AUTOSAR XML (schema 00044)
package /ComponentTypes
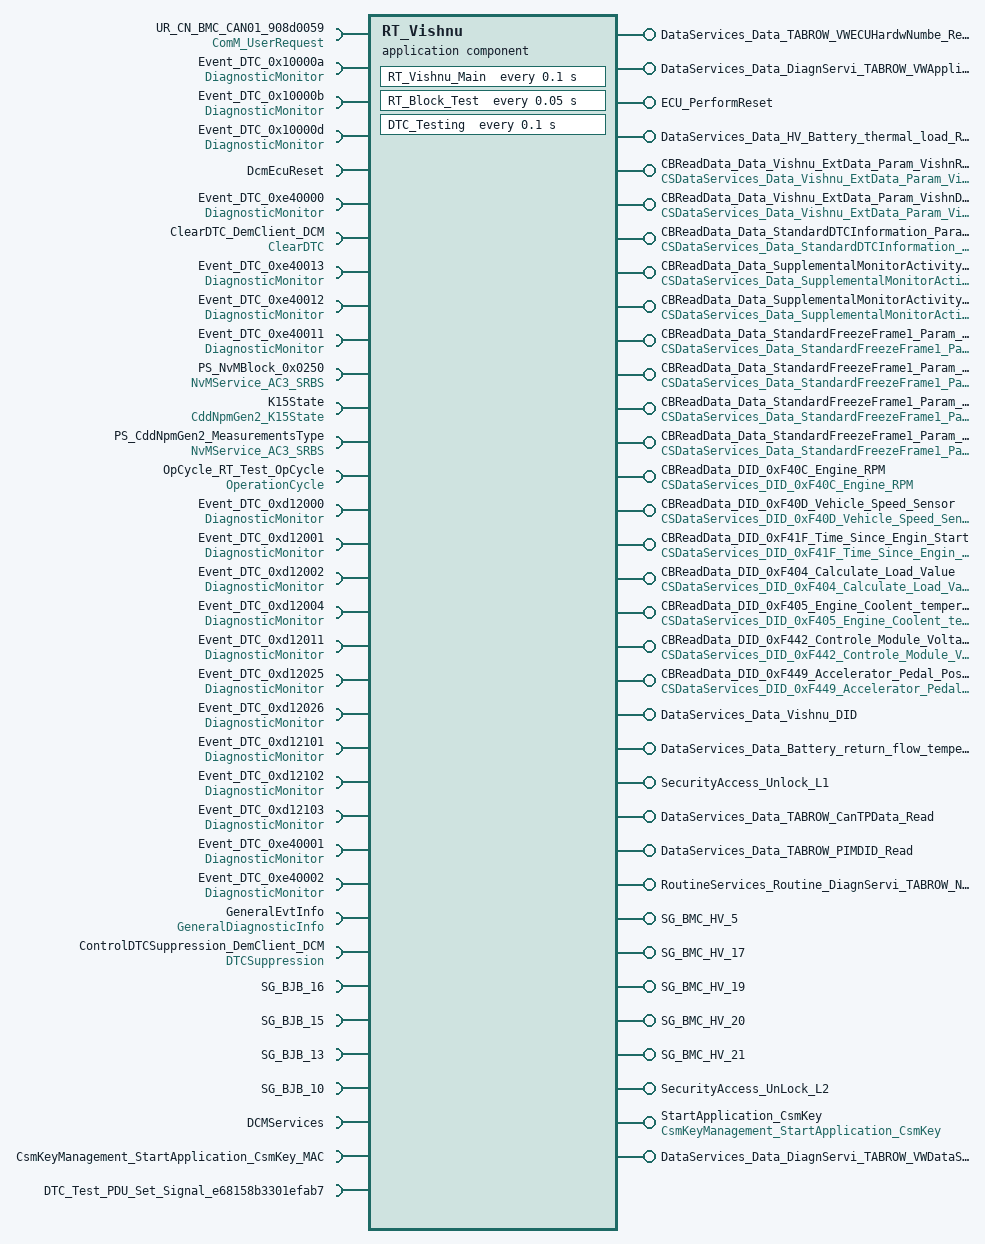
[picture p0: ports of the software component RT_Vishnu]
  application sw component type RT_Vishnu
    require port UR_CN_BMC_CAN01_908d0059: required-com-specs=[RequestComMode, GetCurrentComMode, GetMaxComMode, GetRequestedComMode, GetCurrentPNCComMode], required-interface=ComM_UserRequest
    provide port DataServices_Data_TABROW_VWECUHardwNumbe_Read: provided-com-specs=[{operation=ReadData, queue-length=1}, {operation=ConditionCheckRead, queue-length=1}], provided-interface=DataServices_Data_TABROW_VWECUHardwNumbe_Read
    provide port DataServices_Data_DiagnServi_TABROW_VWAppliSoftwVersiNumbe_Read: provided-com-specs=[{operation=ReadData, queue-length=1}, {operation=ConditionCheckRead, queue-length=1}], provided-interface=DataServices_Data_DiagnServi_TABROW_VWAppliSoftwVersiNumbe_Read
    require port Event_DTC_0x10000a: required-interface=DiagnosticMonitor
      required-com-specs:
        SetEventStatus
        ResetEventStatus
        ResetEventDebounceStatus
        GetEventUdsStatus
        GetEventStatus
        GetEventFailed
        GetEventTested
        GetDTCOfEvent
        GetFaultDetectionCounter
        GetEventFreezeFrameDataEx
        GetEventExtendedDataRecordEx
    require port Event_DTC_0x10000b: required-interface=DiagnosticMonitor
      required-com-specs:
        SetEventStatus
        ResetEventStatus
        ResetEventDebounceStatus
        GetEventUdsStatus
        GetEventStatus
        GetEventFailed
        GetEventTested
        GetDTCOfEvent
        GetFaultDetectionCounter
        GetEventFreezeFrameDataEx
        GetEventExtendedDataRecordEx
    require port Event_DTC_0x10000d: required-interface=DiagnosticMonitor
      required-com-specs:
        SetEventStatus
        ResetEventStatus
        ResetEventDebounceStatus
        GetEventUdsStatus
        GetEventStatus
        GetEventFailed
        GetEventTested
        GetDTCOfEvent
        GetFaultDetectionCounter
        GetEventFreezeFrameDataEx
        GetEventExtendedDataRecordEx
    provide port ECU_PerformReset: mode-switch-sender-com-spec{mode-group=IF_ECU_Perform_Reset_Indication, queue-length=1}, provided-interface=ECU_PerformReset
    require port DcmEcuReset: mode-switch-receiver-com-spec=DcmEcuReset, required-interface=DcmEcuReset
    provide port DataServices_Data_HV_Battery_thermal_load_Read_Data_By_Identifier: provided-com-specs=[{operation=ReadData, queue-length=1}, {operation=ConditionCheckRead, queue-length=1}], provided-interface=DataServices_Data_HV_Battery_thermal_load_Read_Data_By_Identifier
    require port Event_DTC_0xe40000: required-interface=DiagnosticMonitor
      required-com-specs:
        SetEventStatus
        ResetEventStatus
        ResetEventDebounceStatus
        GetEventUdsStatus
        GetEventStatus
        GetEventFailed
        GetEventTested
        GetDTCOfEvent
        GetFaultDetectionCounter
        GetEventFreezeFrameDataEx
        GetEventExtendedDataRecordEx
    provide port CBReadData_Data_Vishnu_ExtData_Param_VishnRes: server-com-spec{operation=ReadData, queue-length=1}, provided-interface=CSDataServices_Data_Vishnu_ExtData_Param_VishnRes
    provide port CBReadData_Data_Vishnu_ExtData_Param_VishnDOB: server-com-spec{operation=ReadData, queue-length=1}, provided-interface=CSDataServices_Data_Vishnu_ExtData_Param_VishnDOB
    provide port CBReadData_Data_StandardDTCInformation_Param_DTCPrior: server-com-spec{operation=ReadData, queue-length=1}, provided-interface=CSDataServices_Data_StandardDTCInformation_Param_DTCPrior
    require port ClearDTC_DemClient_DCM: required-com-specs=[SelectDTC, ClearDTC], required-interface=ClearDTC
    6 x provide port, all with server-com-spec{operation=ReadData, queue-length=1}:
      CBReadData_Data_SupplementalMonitorActivityData_Param_StoreMonitActivRatio: provided-interface=CSDataServices_Data_SupplementalMonitorActivityData_Param_StoreMonitActivRatio
      CBReadData_Data_SupplementalMonitorActivityData_Param_MonitActivNumerCount: provided-interface=CSDataServices_Data_SupplementalMonitorActivityData_Param_MonitActivNumerCount
      CBReadData_Data_StandardFreezeFrame1_Param_TimeStamp_STRUC_Bitfi: provided-interface=CSDataServices_Data_StandardFreezeFrame1_Param_TimeStamp_STRUC_Bitfi
      CBReadData_Data_StandardFreezeFrame1_Param_Reser: provided-interface=CSDataServices_Data_StandardFreezeFrame1_Param_Reser
      CBReadData_Data_StandardFreezeFrame1_Param_KmMilea_1: provided-interface=CSDataServices_Data_StandardFreezeFrame1_Param_KmMilea_1
      CBReadData_Data_StandardFreezeFrame1_Param_AgingCount: provided-interface=CSDataServices_Data_StandardFreezeFrame1_Param_AgingCount
    require port Event_DTC_0xe40013: required-interface=DiagnosticMonitor
      required-com-specs:
        SetEventStatus
        ResetEventStatus
        ResetEventDebounceStatus
        GetEventUdsStatus
        GetEventStatus
        GetEventFailed
        GetEventTested
        GetDTCOfEvent
        GetFaultDetectionCounter
        GetEventFreezeFrameDataEx
        GetEventExtendedDataRecordEx
    require port Event_DTC_0xe40012: required-interface=DiagnosticMonitor
      required-com-specs:
        SetEventStatus
        ResetEventStatus
        ResetEventDebounceStatus
        GetEventUdsStatus
        GetEventStatus
        GetEventFailed
        GetEventTested
        GetDTCOfEvent
        GetFaultDetectionCounter
        GetEventFreezeFrameDataEx
        GetEventExtendedDataRecordEx
    require port Event_DTC_0xe40011: required-interface=DiagnosticMonitor
      required-com-specs:
        SetEventStatus
        ResetEventStatus
        ResetEventDebounceStatus
        GetEventUdsStatus
        GetEventStatus
        GetEventFailed
        GetEventTested
        GetDTCOfEvent
        GetFaultDetectionCounter
        GetEventFreezeFrameDataEx
        GetEventExtendedDataRecordEx
    8 x provide port:
      CBReadData_DID_0xF40C_Engine_RPM: server-com-spec{operation=ReadData, queue-length=1}, provided-interface=CSDataServices_DID_0xF40C_Engine_RPM
      CBReadData_DID_0xF40D_Vehicle_Speed_Sensor: server-com-spec{operation=ReadData, queue-length=1}, provided-interface=CSDataServices_DID_0xF40D_Vehicle_Speed_Sensor
      CBReadData_DID_0xF41F_Time_Since_Engin_Start: server-com-spec{operation=ReadData, queue-length=1}, provided-interface=CSDataServices_DID_0xF41F_Time_Since_Engin_Start
      CBReadData_DID_0xF404_Calculate_Load_Value: server-com-spec{operation=ReadData, queue-length=1}, provided-interface=CSDataServices_DID_0xF404_Calculate_Load_Value
      CBReadData_DID_0xF405_Engine_Coolent_temperature: server-com-spec{operation=ReadData, queue-length=1}, provided-interface=CSDataServices_DID_0xF405_Engine_Coolent_temperature
      CBReadData_DID_0xF442_Controle_Module_Voltage: server-com-spec{operation=ReadData, queue-length=1}, provided-interface=CSDataServices_DID_0xF442_Controle_Module_Voltage
      CBReadData_DID_0xF449_Accelerator_Pedal_Position_D: server-com-spec{operation=ReadData, queue-length=1}, provided-interface=CSDataServices_DID_0xF449_Accelerator_Pedal_Position_D
      DataServices_Data_Vishnu_DID: provided-interface=DataServices_Data_Vishnu_DID
        provided-com-specs:
          operation=ReadData, queue-length=1
          operation=ConditionCheckRead, queue-length=1
          operation=WriteData, queue-length=1
    require port PS_NvMBlock_0x0250: required-com-specs=[GetErrorStatus, SetRamBlockStatus, ReadBlock, WriteBlock, InvalidateNvBlock, EraseBlock], required-interface=NvMService_AC3_SRBS
    provide port DataServices_Data_Battery_return_flow_temperature_Read_Data_By_Identifier: provided-interface=DataServices_Data_Battery_return_flow_temperature_Read_Data_By_Identifier
      provided-com-specs:
        operation=ReadData, queue-length=1
        operation=ConditionCheckRead, queue-length=1
        operation=WriteData, queue-length=1
    provide port SecurityAccess_Unlock_L1: provided-com-specs=[{operation=GetSeed, queue-length=1}, {operation=CompareKey, queue-length=1}], provided-interface=SecurityAccess_Unlock_L1
    require port K15State: client-com-spec=SetK15State, required-interface=CddNpmGen2_K15State
    require port PS_CddNpmGen2_MeasurementsType: required-com-specs=[GetErrorStatus, SetRamBlockStatus, ReadBlock, WriteBlock, InvalidateNvBlock, EraseBlock], required-interface=NvMService_AC3_SRBS
    require port OpCycle_RT_Test_OpCycle: required-com-specs=[GetOperationCycleState, SetOperationCycleState], required-interface=OperationCycle
    provide port DataServices_Data_TABROW_CanTPData_Read: provided-interface=DataServices_Data_TABROW_CanTPData_Read
      provided-com-specs:
        operation=ReadData, queue-length=1
        operation=ConditionCheckRead, queue-length=1
        operation=WriteData, queue-length=1
    provide port DataServices_Data_TABROW_PIMDID_Read: provided-interface=DataServices_Data_TABROW_PIMDID_Read
      provided-com-specs:
        operation=ReadData, queue-length=1
        operation=ConditionCheckRead, queue-length=1
        operation=WriteData, queue-length=1
    provide port RoutineServices_Routine_DiagnServi_TABROW_NewRoutiBasicSetti_Start_Routine: provided-interface=RoutineServices_Routine_DiagnServi_TABROW_NewRoutiBasicSetti_Start_Routine
      provided-com-specs:
        operation=Start, queue-length=1
        operation=Stop, queue-length=1
        operation=RequestResults, queue-length=1
    14 x require port:
      Event_DTC_0xd12000: required-interface=DiagnosticMonitor
        required-com-specs:
          SetEventStatus
          ResetEventStatus
          ResetEventDebounceStatus
          GetEventUdsStatus
          GetEventStatus
          GetEventFailed
          GetEventTested
          GetDTCOfEvent
          GetFaultDetectionCounter
          GetEventFreezeFrameDataEx
          GetEventExtendedDataRecordEx
      Event_DTC_0xd12001: required-interface=DiagnosticMonitor
        required-com-specs:
          SetEventStatus
          ResetEventStatus
          ResetEventDebounceStatus
          GetEventUdsStatus
          GetEventStatus
          GetEventFailed
          GetEventTested
          GetDTCOfEvent
          GetFaultDetectionCounter
          GetEventFreezeFrameDataEx
          GetEventExtendedDataRecordEx
      Event_DTC_0xd12002: required-interface=DiagnosticMonitor
        required-com-specs:
          SetEventStatus
          ResetEventStatus
          ResetEventDebounceStatus
          GetEventUdsStatus
          GetEventStatus
          GetEventFailed
          GetEventTested
          GetDTCOfEvent
          GetFaultDetectionCounter
          GetEventFreezeFrameDataEx
          GetEventExtendedDataRecordEx
      Event_DTC_0xd12004: required-interface=DiagnosticMonitor
        required-com-specs:
          SetEventStatus
          ResetEventStatus
          ResetEventDebounceStatus
          GetEventUdsStatus
          GetEventStatus
          GetEventFailed
          GetEventTested
          GetDTCOfEvent
          GetFaultDetectionCounter
          GetEventFreezeFrameDataEx
          GetEventExtendedDataRecordEx
      Event_DTC_0xd12011: required-interface=DiagnosticMonitor
        required-com-specs:
          SetEventStatus
          ResetEventStatus
          ResetEventDebounceStatus
          GetEventUdsStatus
          GetEventStatus
          GetEventFailed
          GetEventTested
          GetDTCOfEvent
          GetFaultDetectionCounter
          GetEventFreezeFrameDataEx
          GetEventExtendedDataRecordEx
      Event_DTC_0xd12025: required-interface=DiagnosticMonitor
        required-com-specs:
          SetEventStatus
          ResetEventStatus
          ResetEventDebounceStatus
          GetEventUdsStatus
          GetEventStatus
          GetEventFailed
          GetEventTested
          GetDTCOfEvent
          GetFaultDetectionCounter
          GetEventFreezeFrameDataEx
          GetEventExtendedDataRecordEx
      Event_DTC_0xd12026: required-interface=DiagnosticMonitor
        required-com-specs:
          SetEventStatus
          ResetEventStatus
          ResetEventDebounceStatus
          GetEventUdsStatus
          GetEventStatus
          GetEventFailed
          GetEventTested
          GetDTCOfEvent
          GetFaultDetectionCounter
          GetEventFreezeFrameDataEx
          GetEventExtendedDataRecordEx
      Event_DTC_0xd12101: required-interface=DiagnosticMonitor
        required-com-specs:
          SetEventStatus
          ResetEventStatus
          ResetEventDebounceStatus
          GetEventUdsStatus
          GetEventStatus
          GetEventFailed
          GetEventTested
          GetDTCOfEvent
          GetFaultDetectionCounter
          GetEventFreezeFrameDataEx
          GetEventExtendedDataRecordEx
      Event_DTC_0xd12102: required-interface=DiagnosticMonitor
        required-com-specs:
          SetEventStatus
          ResetEventStatus
          ResetEventDebounceStatus
          GetEventUdsStatus
          GetEventStatus
          GetEventFailed
          GetEventTested
          GetDTCOfEvent
          GetFaultDetectionCounter
          GetEventFreezeFrameDataEx
          GetEventExtendedDataRecordEx
      Event_DTC_0xd12103: required-interface=DiagnosticMonitor
        required-com-specs:
          SetEventStatus
          ResetEventStatus
          ResetEventDebounceStatus
          GetEventUdsStatus
          GetEventStatus
          GetEventFailed
          GetEventTested
          GetDTCOfEvent
          GetFaultDetectionCounter
          GetEventFreezeFrameDataEx
          GetEventExtendedDataRecordEx
      Event_DTC_0xe40001: required-interface=DiagnosticMonitor
        required-com-specs:
          SetEventStatus
          ResetEventStatus
          ResetEventDebounceStatus
          GetEventUdsStatus
          GetEventStatus
          GetEventFailed
          GetEventTested
          GetDTCOfEvent
          GetFaultDetectionCounter
          GetEventFreezeFrameDataEx
          GetEventExtendedDataRecordEx
      Event_DTC_0xe40002: required-interface=DiagnosticMonitor
        required-com-specs:
          SetEventStatus
          ResetEventStatus
          ResetEventDebounceStatus
          GetEventUdsStatus
          GetEventStatus
          GetEventFailed
          GetEventTested
          GetDTCOfEvent
          GetFaultDetectionCounter
          GetEventFreezeFrameDataEx
          GetEventExtendedDataRecordEx
      GeneralEvtInfo: required-interface=GeneralDiagnosticInfo
        required-com-specs:
          GetEventUdsStatus
          GetEventStatus
          GetEventFailed
          GetEventTested
          GetDTCOfEvent
          GetFaultDetectionCounter
          GetEventFreezeFrameDataEx
          GetEventExtendedDataRecordEx
          GetEventEnableCondition
          GetDebouncingOfEvent
          GetMonitorStatus
      ControlDTCSuppression_DemClient_DCM: required-com-specs=[SetDTCSuppression, GetDTCSuppression], required-interface=DTCSuppression
    5 x provide port:
      SG_BMC_HV_5: nonqueued-sender-com-spec{data-element=SG_BMC_HV_04, init-value=fields=[BMC_Dev_Freigabe:0, BMC_Flash_Freigabe:0, BMC_HV_04_BZ:0, BMC_HV_04_CRC:0, BMC_Iso_Mode_Anf:0, BMC_UI1_Spannung1_Schalt_Anf:0, BMC_UI1_Spannung2_Schalt_Anf:0, BMC_UI2_Spannung1_Schalt_Anf:0, BMC_UI2_Spannung2_Schalt_Anf:0, SignalVoid_BMC_HV_04_0:0, SignalVoid_BMC_HV_04_1:0, SignalVoid_BMC_HV_04_2:0, SignalVoid_BMC_HV_04_3:0, SignalVoid_BMC_HV_04_4:0, SignalVoid_BMC_HV_04_5:0]}, provided-interface=SG_BMC_HV_5
      SG_BMC_HV_17: nonqueued-sender-com-spec{data-element=SG_BMC_HV_10, init-value=fields=[BMC_Datenuebernahme_Anf:0, BMC_HV_10_BZ:0, BMC_HV_10_CRC:0, BMC_Lebensdauer_Trennelemente:0, BMC_Sperrung_Unterspannung:0, BMC_Status_HV_Spannungssensorik:0, BMC_Status_Trennelemente:0, SignalVoid_BMC_HV_10_0:0, SignalVoid_BMC_HV_10_1:0, SignalVoid_BMC_HV_10_2:0, SignalVoid_BMC_HV_10_3:0]}, provided-interface=SG_BMC_HV_17
      SG_BMC_HV_19: nonqueued-sender-com-spec{data-element=SG_BMC_HV_11, init-value=fields=[BMC_HV_11_BZ:0, BMC_HV_11_CRC:0, BMC_Sperrung_Ueberspannung:0, BMC_Ueberspannungszaehler_CMC01:0, BMC_Ueberspannungszaehler_CMC02:0, BMC_Uebertemperaturzaehler_CMC01:0, BMC_Uebertemperaturzaehler_CMC02:0]}, provided-interface=SG_BMC_HV_19
      SG_BMC_HV_20: nonqueued-sender-com-spec{data-element=SG_BMC_HV_12, init-value=fields=[BMC_HV_12_BZ:0, BMC_HV_12_CRC:0, BMC_Sperrung_Uebertemperatur:0, BMC_Ueberspannungszaehler_CMC03:0, BMC_Ueberspannungszaehler_CMC04:0, BMC_Uebertemperaturzaehler_CMC03:0, BMC_Uebertemperaturzaehler_CMC04:0]}, provided-interface=SG_BMC_HV_20
      SG_BMC_HV_21: nonqueued-sender-com-spec{data-element=SG_BMC_HV_13, init-value=fields=[BMC_HV_13_BZ:0, BMC_HV_13_CRC:0, BMC_Unterspannungszaehler_CMC01:0, BMC_Unterspannungszaehler_CMC02:0, BMC_Unterspannungszaehler_CMC03:0, BMC_Unterspannungszaehler_CMC04:0, SignalVoid_BMC_HV_13_0:0, SignalVoid_BMC_HV_13_1:0]}, provided-interface=SG_BMC_HV_21
    4 x require port:
      SG_BJB_16: nonqueued-receiver-com-spec{data-element=SG_BJB_13, filter=data-filter-type=ALWAYS, init-value=fields=[BJB_13_BZ:0, BJB_13_CRC:0, BJB_Unterspannungszaehler_CMC01:0, BJB_Unterspannungszaehler_CMC02:0, BJB_Unterspannungszaehler_CMC03:0, BJB_Unterspannungszaehler_CMC04:0, SignalVoid_BJB_13_0:0, SignalVoid_BJB_13_1:0]}, required-interface=SG_BJB_16
      SG_BJB_15: nonqueued-receiver-com-spec{data-element=SG_BJB_12, filter=data-filter-type=ALWAYS, init-value=fields=[BJB_12_BZ:0, BJB_12_CRC:0, BJB_Sperrung_Uebertemperatur:0, BJB_Ueberspannungszaehler_CMC03:0, BJB_Ueberspannungszaehler_CMC04:0, BJB_Uebertemperaturzaehler_CMC03:0, BJB_Uebertemperaturzaehler_CMC04:0]}, required-interface=SG_BJB_15
      SG_BJB_13: nonqueued-receiver-com-spec{data-element=SG_BJB_11, filter=data-filter-type=ALWAYS, init-value=fields=[BJB_11_BZ:0, BJB_11_CRC:0, BJB_Sperrung_Ueberspannung:0, BJB_Ueberspannungszaehler_CMC01:0, BJB_Ueberspannungszaehler_CMC02:0, BJB_Uebertemperaturzaehler_CMC01:0, BJB_Uebertemperaturzaehler_CMC02:0]}, required-interface=SG_BJB_13
      SG_BJB_10: nonqueued-receiver-com-spec{data-element=SG_BJB_10, filter=data-filter-type=ALWAYS, init-value=fields=[BJB_10_BZ:0, BJB_10_CRC:0, BJB_Lebensdauer_Trennelemente:0, BJB_Sperrung_Unterspannung:0, BJB_Status_HV_Spannungssensorik:0, BJB_Status_Trennelemente:0, SignalVoid_BJB_10_0:0, SignalVoid_BJB_10_1:0, SignalVoid_BJB_10_2:0, SignalVoid_BJB_10_3:0]}, required-interface=SG_BJB_10
    provide port SecurityAccess_UnLock_L2: provided-com-specs=[{operation=GetSeed, queue-length=1}, {operation=CompareKey, queue-length=1}], provided-interface=SecurityAccess_UnLock_L2
    require port DCMServices: required-interface=DCMServices
      required-com-specs:
        GetSecurityLevel
        GetRequestKind
        SetActiveDiagnostic
        ResetToDefaultSession
        GetSesCtrlType
        GetActiveProtocol
    provide port StartApplication_CsmKey: provided-interface=CsmKeyManagement_StartApplication_CsmKey
      provided-com-specs:
        operation=KeyElementCopyPartial, queue-length=1
        operation=RandomSeed, queue-length=1
        operation=KeySetValid, queue-length=1
        operation=KeyGenerate, queue-length=1
        operation=KeyExchangeCalcSecret, queue-length=1
        operation=KeyExchangeCalcPubVal, queue-length=1
        operation=KeyElementSet, queue-length=1
        operation=KeyElementGet, queue-length=1
        operation=KeyElementCopy, queue-length=1
        operation=KeyDerive, queue-length=1
        operation=KeyCopy, queue-length=1
        operation=CertificateVerify, queue-length=1
        operation=CertificateParse, queue-length=1
    require port CsmKeyManagement_StartApplication_CsmKey_MAC: required-interface=CsmKeyManagement_StartApplication_CsmKey_MAC
      required-com-specs:
        RandomSeed
        KeySetValid
        KeyGenerate
        KeyExchangeCalcSecret
        KeyExchangeCalcPubVal
        KeyElementSet
        KeyElementGet
        KeyElementCopyPartial
        KeyElementCopy
        KeyDerive
        KeyCopy
        CertificateVerify
        CertificateParse
    provide port DataServices_Data_DiagnServi_TABROW_VWDataSetNumbeOrECUDataContaNumbe_Read: provided-interface=DataServices_Data_DiagnServi_TABROW_VWDataSetNumbeOrECUDataContaNumbe_Read
      provided-com-specs:
        operation=ReadData, queue-length=1
        operation=ConditionCheckRead, queue-length=1
        operation=WriteData, queue-length=1
    require port DTC_Test_PDU_Set_Signal_e68158b3301efab7: nonqueued-receiver-com-spec{data-element=DTC_Test_PDU_Set_Signal_e68158b3301efab7, filter=data-filter-type=ALWAYS, init-value=0}, required-interface=DTC_Test_PDU_Set_Signal_e68158b3301efab7
    behavior RT_Vishnu_InternalBehavior: data-type-mapping=defaultDataTypeMappingSet_CPFS
      init event RT_Vishnu_InitEvent: start-on-event=RT_Vishnu_Init
      timing event TMT_RT_Vishnu_Main: start-on-event=RT_Vishnu_Main, period=0.1
      30 x operation invoked event:
        OIT_DataServices_Data_TABROW_VWECUHardwNumbe_Read_ConditionCheckRead_DataServices_Data_TABROW_VWECUHardwNumbe_Read_Condi47CE08D0: start-on-event=DataServices_Data_TABROW_VWECUHardwNumbe_Read_ConditionCheckRead, operation=DataServices_Data_TABROW_VWECUHardwNumbe_Read.ConditionCheckRead
        OIT_DataServices_Data_TABROW_VWECUHardwNumbe_Read_ReadData_DataServices_Data_TABROW_VWECUHardwNumbe_Read_ReadData: start-on-event=DataServices_Data_TABROW_VWECUHardwNumbe_Read_ReadData, operation=DataServices_Data_TABROW_VWECUHardwNumbe_Read.ReadData
        OIT_DataServices_Data_DiagnServi_TABROW_VWAppliSoftwVersiNumbe_Read_ConditionCheckRead_DataServices_Data_DiagnServi_TABRA8B5CA8D: start-on-event=DataServices_Data_DiagnServi_TABROW_VWAppliSoftwVersiNumbe_Read_ConditionCheckRead, operation=DataServices_Data_DiagnServi_TABROW_VWAppliSoftwVersiNumbe_Read.ConditionCheckRead
        OIT_DataServices_Data_DiagnServi_TABROW_VWAppliSoftwVersiNumbe_Read_ReadData_DataServices_Data_DiagnServi_TABROW_VWAppli12F0F5D6: start-on-event=DataServices_Data_DiagnServi_TABROW_VWAppliSoftwVersiNumbe_Read_ReadData, operation=DataServices_Data_DiagnServi_TABROW_VWAppliSoftwVersiNumbe_Read.ReadData
        OIT_DataServices_Data_HV_Battery_thermal_load_Read_Data_By_Identifier_ConditionCheckRead_DataServices_Data_HV_Battery_th4ECF83C6: start-on-event=DataServices_Data_HV_Battery_thermal_load_Read_Data_By_Identifier_ConditionCheckRead, operation=DataServices_Data_HV_Battery_thermal_load_Read_Data_By_Identifier.ConditionCheckRead
        OIT_DataServices_Data_HV_Battery_thermal_load_Read_Data_By_Identifier_ReadData_DataServices_Data_HV_Battery_thermal_loadAB9512D1: start-on-event=DataServices_Data_HV_Battery_thermal_load_Read_Data_By_Identifier_ReadData, operation=DataServices_Data_HV_Battery_thermal_load_Read_Data_By_Identifier.ReadData
        OIT_CBReadData_Data_Vishnu_ExtData_Param_VishnRes_ReadData_CBReadData_Data_Vishnu_ExtData_Param_VishnRes_ReadData: start-on-event=CBReadData_Data_Vishnu_ExtData_Param_VishnRes_ReadData, operation=CBReadData_Data_Vishnu_ExtData_Param_VishnRes.ReadData
        OIT_CBReadData_Data_Vishnu_ExtData_Param_VishnDOB_ReadData_CBReadData_Data_Vishnu_ExtData_Param_VishnDOB_ReadData: start-on-event=CBReadData_Data_Vishnu_ExtData_Param_VishnDOB_ReadData, operation=CBReadData_Data_Vishnu_ExtData_Param_VishnDOB.ReadData
        OIT_CBReadData_Data_StandardDTCInformation_Param_DTCPrior_ReadData_CBReadData_Data_StandardDTCInformation_Param_DTCPrior11C735F0: start-on-event=CBReadData_Data_StandardDTCInformation_Param_DTCPrior_ReadData, operation=CBReadData_Data_StandardDTCInformation_Param_DTCPrior.ReadData
        OIT_CBReadData_Data_SupplementalMonitorActivityData_Param_StoreMonitActivRatio_ReadData_CBReadData_Data_SupplementalMoni9EBADFB6: start-on-event=CBReadData_Data_SupplementalMonitorActivityData_Param_StoreMonitActivRatio_ReadData, operation=CBReadData_Data_SupplementalMonitorActivityData_Param_StoreMonitActivRatio.ReadData
        OIT_CBReadData_Data_SupplementalMonitorActivityData_Param_MonitActivNumerCount_ReadData_CBReadData_Data_SupplementalMoniC2ADAA2D: start-on-event=CBReadData_Data_SupplementalMonitorActivityData_Param_MonitActivNumerCount_ReadData, operation=CBReadData_Data_SupplementalMonitorActivityData_Param_MonitActivNumerCount.ReadData
        OIT_CBReadData_Data_StandardFreezeFrame1_Param_TimeStamp_STRUC_Bitfi_ReadData_CBReadData_Data_StandardFreezeFrame1_Param13E4A54C: start-on-event=CBReadData_Data_StandardFreezeFrame1_Param_TimeStamp_STRUC_Bitfi_ReadData, operation=CBReadData_Data_StandardFreezeFrame1_Param_TimeStamp_STRUC_Bitfi.ReadData
        OIT_CBReadData_Data_StandardFreezeFrame1_Param_Reser_ReadData_CBReadData_Data_StandardFreezeFrame1_Param_Reser_ReadData: start-on-event=CBReadData_Data_StandardFreezeFrame1_Param_Reser_ReadData, operation=CBReadData_Data_StandardFreezeFrame1_Param_Reser.ReadData
        OIT_CBReadData_Data_StandardFreezeFrame1_Param_KmMilea_1_ReadData_CBReadData_Data_StandardFreezeFrame1_Param_KmMilea_1_ReadData: start-on-event=CBReadData_Data_StandardFreezeFrame1_Param_KmMilea_1_ReadData, operation=CBReadData_Data_StandardFreezeFrame1_Param_KmMilea_1.ReadData
        OIT_CBReadData_Data_StandardFreezeFrame1_Param_AgingCount_ReadData_CBReadData_Data_StandardFreezeFrame1_Param_AgingCount6B461DD3: start-on-event=CBReadData_Data_StandardFreezeFrame1_Param_AgingCount_ReadData, operation=CBReadData_Data_StandardFreezeFrame1_Param_AgingCount.ReadData
        OIT_CBReadData_DID_0xF41F_Time_Since_Engin_Start_ReadData_CBReadData_DID_0xF41F_Time_Since_Engin_Start_ReadData: start-on-event=CBReadData_DID_0xF41F_Time_Since_Engin_Start_ReadData, operation=CBReadData_DID_0xF41F_Time_Since_Engin_Start.ReadData
        OIT_CBReadData_DID_0xF449_Accelerator_Pedal_Position_D_ReadData_CBReadData_DID_0xF449_Accelerator_Pedal_Position_D_ReadData: start-on-event=CBReadData_DID_0xF449_Accelerator_Pedal_Position_D_ReadData, operation=CBReadData_DID_0xF449_Accelerator_Pedal_Position_D.ReadData
        OIT_CBReadData_DID_0xF404_Calculate_Load_Value_ReadData_CBReadData_DID_0xF404_Calculate_Load_Value_ReadData: start-on-event=CBReadData_DID_0xF404_Calculate_Load_Value_ReadData, operation=CBReadData_DID_0xF404_Calculate_Load_Value.ReadData
        OIT_CBReadData_DID_0xF442_Controle_Module_Voltage_ReadData_CBReadData_DID_0xF442_Controle_Module_Voltage_ReadData: start-on-event=CBReadData_DID_0xF442_Controle_Module_Voltage_ReadData, operation=CBReadData_DID_0xF442_Controle_Module_Voltage.ReadData
        OIT_CBReadData_DID_0xF40D_Vehicle_Speed_Sensor_ReadData_CBReadData_DID_0xF40D_Vehicle_Speed_Sensor_ReadData: start-on-event=CBReadData_DID_0xF40D_Vehicle_Speed_Sensor_ReadData, operation=CBReadData_DID_0xF40D_Vehicle_Speed_Sensor.ReadData
        OIT_CBReadData_DID_0xF40C_Engine_RPM_ReadData_CBReadData_DID_0xF40C_Engine_RPM_ReadData: start-on-event=CBReadData_DID_0xF40C_Engine_RPM_ReadData, operation=CBReadData_DID_0xF40C_Engine_RPM.ReadData
        OIT_CBReadData_DID_0xF405_Engine_Coolent_temperature_ReadData_CBReadData_DID_0xF405_Engine_Coolent_temperature_ReadData: start-on-event=CBReadData_DID_0xF405_Engine_Coolent_temperature_ReadData, operation=CBReadData_DID_0xF405_Engine_Coolent_temperature.ReadData
        OIT_DataServices_Data_Vishnu_DID_WriteData_DataServices_Data_Vishnu_DID_WriteData: start-on-event=DataServices_Data_Vishnu_DID_WriteData, operation=DataServices_Data_Vishnu_DID.WriteData
        OIT_DataServices_Data_Vishnu_DID_ConditionCheckRead_DataServices_Data_Vishnu_DID_ConditionCheckRead: start-on-event=DataServices_Data_Vishnu_DID_ConditionCheckRead, operation=DataServices_Data_Vishnu_DID.ConditionCheckRead
        OIT_DataServices_Data_Vishnu_DID_ReadData_DataServices_Data_Vishnu_DID_ReadData: start-on-event=DataServices_Data_Vishnu_DID_ReadData, operation=DataServices_Data_Vishnu_DID.ReadData
        OIT_DataServices_Data_Battery_return_flow_temperature_Read_Data_By_Identifier_WriteData_DataServices_Data_Battery_returnA8FDE068: start-on-event=DataServices_Data_Battery_return_flow_temperature_Read_Data_By_Identifier_WriteData, operation=DataServices_Data_Battery_return_flow_temperature_Read_Data_By_Identifier.WriteData
        OIT_DataServices_Data_Battery_return_flow_temperature_Read_Data_By_Identifier_ConditionCheckRead_DataServices_Data_Batte8DED2CB7: start-on-event=DataServices_Data_Battery_return_flow_temperature_Read_Data_By_Identifier_ConditionCheckRead, operation=DataServices_Data_Battery_return_flow_temperature_Read_Data_By_Identifier.ConditionCheckRead
        OIT_DataServices_Data_Battery_return_flow_temperature_Read_Data_By_Identifier_ReadData_DataServices_Data_Battery_return_62621C5A: start-on-event=DataServices_Data_Battery_return_flow_temperature_Read_Data_By_Identifier_ReadData, operation=DataServices_Data_Battery_return_flow_temperature_Read_Data_By_Identifier.ReadData
        OIT_SecurityAccess_Unlock_L1_CompareKey_SecurityAccess_Unlock_L1_CompareKey: start-on-event=SecurityAccess_Unlock_L1_CompareKey, operation=SecurityAccess_Unlock_L1.CompareKey
        OIT_SecurityAccess_Unlock_L1_GetSeed_SecurityAccess_Unlock_L1_GetSeed: start-on-event=SecurityAccess_Unlock_L1_GetSeed, operation=SecurityAccess_Unlock_L1.GetSeed
      timing event TMT_RT_Block_Test: start-on-event=RT_Block_Test, period=0.05
      timing event TMT_DTC_Testing: start-on-event=DTC_Testing, period=0.1
      14 x operation invoked event:
        OIT_DataServices_Data_TABROW_CanTPData_Read_WriteData_DataServices_Data_TABROW_CanTPData_Read_WriteData: start-on-event=DataServices_Data_TABROW_CanTPData_Read_WriteData, operation=DataServices_Data_TABROW_CanTPData_Read.WriteData
        OIT_DataServices_Data_TABROW_CanTPData_Read_ConditionCheckRead_DataServices_Data_TABROW_CanTPData_Read_ConditionCheckRead: start-on-event=DataServices_Data_TABROW_CanTPData_Read_ConditionCheckRead, operation=DataServices_Data_TABROW_CanTPData_Read.ConditionCheckRead
        OIT_DataServices_Data_TABROW_CanTPData_Read_ReadData_DataServices_Data_TABROW_CanTPData_Read_ReadData: start-on-event=DataServices_Data_TABROW_CanTPData_Read_ReadData, operation=DataServices_Data_TABROW_CanTPData_Read.ReadData
        OIT_DataServices_Data_TABROW_PIMDID_Read_WriteData_DataServices_Data_TABROW_PIMDID_Read_WriteData: start-on-event=DataServices_Data_TABROW_PIMDID_Read_WriteData, operation=DataServices_Data_TABROW_PIMDID_Read.WriteData
        OIT_DataServices_Data_TABROW_PIMDID_Read_ConditionCheckRead_DataServices_Data_TABROW_PIMDID_Read_ConditionCheckRead: start-on-event=DataServices_Data_TABROW_PIMDID_Read_ConditionCheckRead, operation=DataServices_Data_TABROW_PIMDID_Read.ConditionCheckRead
        OIT_DataServices_Data_TABROW_PIMDID_Read_ReadData_DataServices_Data_TABROW_PIMDID_Read_ReadData: start-on-event=DataServices_Data_TABROW_PIMDID_Read_ReadData, operation=DataServices_Data_TABROW_PIMDID_Read.ReadData
        OIT_RoutineServices_Routine_DiagnServi_TABROW_NewRoutiBasicSetti_Start_Routine_RequestResults_RoutineServices_Routine_Di7D6384C0: start-on-event=RoutineServices_Routine_DiagnServi_TABROW_NewRoutiBasicSetti_Start_Routine_RequestResults, operation=RoutineServices_Routine_DiagnServi_TABROW_NewRoutiBasicSetti_Start_Routine.RequestResults
        OIT_RoutineServices_Routine_DiagnServi_TABROW_NewRoutiBasicSetti_Start_Routine_Stop_RoutineServices_Routine_DiagnServi_T8284D060: start-on-event=RoutineServices_Routine_DiagnServi_TABROW_NewRoutiBasicSetti_Start_Routine_Stop, operation=RoutineServices_Routine_DiagnServi_TABROW_NewRoutiBasicSetti_Start_Routine.Stop
        OIT_RoutineServices_Routine_DiagnServi_TABROW_NewRoutiBasicSetti_Start_Routine_Start_RoutineServices_Routine_DiagnServi_962E3252: start-on-event=RoutineServices_Routine_DiagnServi_TABROW_NewRoutiBasicSetti_Start_Routine_Start, operation=RoutineServices_Routine_DiagnServi_TABROW_NewRoutiBasicSetti_Start_Routine.Start
        OIT_SecurityAccess_UnLock_L2_CompareKey_SecurityAccess_UnLock_L2_CompareKey: start-on-event=SecurityAccess_UnLock_L2_CompareKey, operation=SecurityAccess_UnLock_L2.CompareKey
        OIT_SecurityAccess_UnLock_L2_GetSeed_SecurityAccess_UnLock_L2_GetSeed: start-on-event=SecurityAccess_UnLock_L2_GetSeed, operation=SecurityAccess_UnLock_L2.GetSeed
        OIT_DataServices_Data_DiagnServi_TABROW_VWDataSetNumbeOrECUDataContaNumbe_Read_WriteData_DataServices_Data_DiagnServi_TA51303A80: start-on-event=DataServices_Data_DiagnServi_TABROW_VWDataSetNumbeOrECUDataContaNumbe_Read_WriteData, operation=DataServices_Data_DiagnServi_TABROW_VWDataSetNumbeOrECUDataContaNumbe_Read.WriteData
        OIT_DataServices_Data_DiagnServi_TABROW_VWDataSetNumbeOrECUDataContaNumbe_Read_ConditionCheckRead_DataServices_Data_DiagE14091CD: start-on-event=DataServices_Data_DiagnServi_TABROW_VWDataSetNumbeOrECUDataContaNumbe_Read_ConditionCheckRead, operation=DataServices_Data_DiagnServi_TABROW_VWDataSetNumbeOrECUDataContaNumbe_Read.ConditionCheckRead
        OIT_DataServices_Data_DiagnServi_TABROW_VWDataSetNumbeOrECUDataContaNumbe_Read_ReadData_DataServices_Data_DiagnServi_TAB7D0A9581: start-on-event=DataServices_Data_DiagnServi_TABROW_VWDataSetNumbeOrECUDataContaNumbe_Read_ReadData, operation=DataServices_Data_DiagnServi_TABROW_VWDataSetNumbeOrECUDataContaNumbe_Read.ReadData
      port-api-options:
        enable-take-address=true, error-handling=NO-TRANSFORMER-ERROR-HANDLING, indirect-api=false, port=ClearDTC_DemClient_DCM
        enable-take-address=true, error-handling=NO-TRANSFORMER-ERROR-HANDLING, indirect-api=false, port=CBReadData_DID_0xF40C_Engine_RPM
        enable-take-address=true, error-handling=NO-TRANSFORMER-ERROR-HANDLING, indirect-api=false, port=CBReadData_DID_0xF40D_Vehicle_Speed_Sensor
        enable-take-address=true, error-handling=NO-TRANSFORMER-ERROR-HANDLING, indirect-api=false, port=CBReadData_DID_0xF41F_Time_Since_Engin_Start
        enable-take-address=true, error-handling=NO-TRANSFORMER-ERROR-HANDLING, indirect-api=false, port=CBReadData_DID_0xF404_Calculate_Load_Value
        enable-take-address=true, error-handling=NO-TRANSFORMER-ERROR-HANDLING, indirect-api=false, port=CBReadData_DID_0xF405_Engine_Coolent_temperature
        enable-take-address=true, error-handling=NO-TRANSFORMER-ERROR-HANDLING, indirect-api=false, port=CBReadData_DID_0xF442_Controle_Module_Voltage
        enable-take-address=true, error-handling=NO-TRANSFORMER-ERROR-HANDLING, indirect-api=false, port=CBReadData_DID_0xF449_Accelerator_Pedal_Position_D
        enable-take-address=false, error-handling=NO-TRANSFORMER-ERROR-HANDLING, indirect-api=false, port=PS_NvMBlock_0x0250
        enable-take-address=true, error-handling=NO-TRANSFORMER-ERROR-HANDLING, indirect-api=false, port=DCMServices
        {enable-take-address=true, error-handling=NO-TRANSFORMER-ERROR-HANDLING, indirect-api=false, port-defined-argument-value{value=keyId:29, value-type=uint32}, port=StartApplication_CsmKey}
      49 x runnable:
        RT_Vishnu_Init
          sync call SC_UR_CN_BMC_CAN01_908d0059_RequestComMode: operation=UR_CN_BMC_CAN01_908d0059.RequestComMode
        RT_Vishnu_Main: mode-access-point=DcmEcuReset.DcmEcuReset
          data-receive-point-by-arguments:
            4 x access:
              REC_SG_BJB_10_SG_BJB_10: accessed-variable=SG_BJB_10.SG_BJB_10
              REC_SG_BJB_13_SG_BJB_11: accessed-variable=SG_BJB_13.SG_BJB_11
              REC_SG_BJB_15_SG_BJB_12: accessed-variable=SG_BJB_15.SG_BJB_12
              REC_SG_BJB_16_SG_BJB_13: accessed-variable=SG_BJB_16.SG_BJB_13
          data-send-points:
            5 x access:
              SEND_SG_BMC_HV_17_SG_BMC_HV_10: accessed-variable=SG_BMC_HV_17.SG_BMC_HV_10
              SEND_SG_BMC_HV_19_SG_BMC_HV_11: accessed-variable=SG_BMC_HV_19.SG_BMC_HV_11
              SEND_SG_BMC_HV_20_SG_BMC_HV_12: accessed-variable=SG_BMC_HV_20.SG_BMC_HV_12
              SEND_SG_BMC_HV_21_SG_BMC_HV_13: accessed-variable=SG_BMC_HV_21.SG_BMC_HV_13
              SEND_SG_BMC_HV_5_SG_BMC_HV_04: accessed-variable=SG_BMC_HV_5.SG_BMC_HV_04
          mode switch point SWITCH_ECU_PerformReset_IF_ECU_Perform_Reset_Indication: mode-group=ECU_PerformReset.IF_ECU_Perform_Reset_Indication
          10 x sync call:
            SC_PS_NvMBlock_0x0250_ReadBlock: operation=PS_NvMBlock_0x0250.ReadBlock
            SC_PS_NvMBlock_0x0250_WriteBlock: operation=PS_NvMBlock_0x0250.WriteBlock
            SC_K15State_SetK15State: operation=K15State.SetK15State
            SC_DCMServices_GetActiveProtocol: operation=DCMServices.GetActiveProtocol
            SC_DCMServices_GetRequestKind: operation=DCMServices.GetRequestKind
            SC_DCMServices_GetSecurityLevel: operation=DCMServices.GetSecurityLevel
            SC_DCMServices_GetSesCtrlType: operation=DCMServices.GetSesCtrlType
            SC_DCMServices_ResetToDefaultSession: operation=DCMServices.ResetToDefaultSession
            SC_DCMServices_SetActiveDiagnostic: operation=DCMServices.SetActiveDiagnostic
            SC_CsmKeyManagement_StartApplication_CsmKey_MAC_KeyGenerate: operation=CsmKeyManagement_StartApplication_CsmKey_MAC.KeyGenerate
        DataServices_Data_TABROW_VWECUHardwNumbe_Read_ConditionCheckRead
        DataServices_Data_TABROW_VWECUHardwNumbe_Read_ReadData
        DataServices_Data_DiagnServi_TABROW_VWAppliSoftwVersiNumbe_Read_ConditionCheckRead
        DataServices_Data_DiagnServi_TABROW_VWAppliSoftwVersiNumbe_Read_ReadData
        DataServices_Data_HV_Battery_thermal_load_Read_Data_By_Identifier_ConditionCheckRead
        DataServices_Data_HV_Battery_thermal_load_Read_Data_By_Identifier_ReadData
        CBReadData_Data_Vishnu_ExtData_Param_VishnRes_ReadData
        CBReadData_Data_Vishnu_ExtData_Param_VishnDOB_ReadData
        CBReadData_Data_StandardDTCInformation_Param_DTCPrior_ReadData
        CBReadData_Data_StandardDTCInformation_Param_OccurCount_ReadData
        CBReadData_Data_SupplementalMonitorActivityData_Param_StoreMonitActivRatio_ReadData
        CBReadData_Data_SupplementalMonitorActivityData_Param_MonitActivNumerCount_ReadData
        CBReadData_Data_StandardFreezeFrame1_Param_TimeStamp_STRUC_Bitfi_ReadData
        CBReadData_Data_StandardFreezeFrame1_Param_Reser_ReadData
        CBReadData_Data_StandardFreezeFrame1_Param_KmMilea_1_ReadData
        CBReadData_Data_StandardFreezeFrame1_Param_AgingCount_ReadData
        CBReadData_DID_0xF41F_Time_Since_Engin_Start_ReadData
        CBReadData_DID_0xF449_Accelerator_Pedal_Position_D_ReadData
        CBReadData_DID_0xF404_Calculate_Load_Value_ReadData
        CBReadData_DID_0xF442_Controle_Module_Voltage_ReadData
        CBReadData_DID_0xF40D_Vehicle_Speed_Sensor_ReadData
        CBReadData_DID_0xF40C_Engine_RPM_ReadData
        CBReadData_DID_0xF405_Engine_Coolent_temperature_ReadData
        DataServices_Data_Vishnu_DID_WriteData
        DataServices_Data_Vishnu_DID_ConditionCheckRead
        DataServices_Data_Vishnu_DID_ReadData
        DataServices_Data_Battery_return_flow_temperature_Read_Data_By_Identifier_WriteData
        DataServices_Data_Battery_return_flow_temperature_Read_Data_By_Identifier_ConditionCheckRead
        DataServices_Data_Battery_return_flow_temperature_Read_Data_By_Identifier_ReadData
        SecurityAccess_Unlock_L1_CompareKey
        SecurityAccess_Unlock_L1_GetSeed
        RT_Block_Test
          6 x sync call:
            SC_PS_CddNpmGen2_MeasurementsType_EraseBlock: operation=PS_CddNpmGen2_MeasurementsType.EraseBlock
            SC_PS_CddNpmGen2_MeasurementsType_GetErrorStatus: operation=PS_CddNpmGen2_MeasurementsType.GetErrorStatus
            SC_PS_CddNpmGen2_MeasurementsType_InvalidateNvBlock: operation=PS_CddNpmGen2_MeasurementsType.InvalidateNvBlock
            SC_PS_CddNpmGen2_MeasurementsType_ReadBlock: operation=PS_CddNpmGen2_MeasurementsType.ReadBlock
            SC_PS_CddNpmGen2_MeasurementsType_SetRamBlockStatus: operation=PS_CddNpmGen2_MeasurementsType.SetRamBlockStatus
            SC_PS_CddNpmGen2_MeasurementsType_WriteBlock: operation=PS_CddNpmGen2_MeasurementsType.WriteBlock
        DTC_Testing
          data-receive-point-by-arguments:
            access REC_DTC_Test_PDU_Set_Signal_e68158b3301efab7_DTC_Test_PDU_Set_Signal_e68158b3301efab7: accessed-variable=DTC_Test_PDU_Set_Signal_e68158b3301efab7.DTC_Test_PDU_Set_Signal_e68158b3301efab7
          25 x sync call:
            SC_Event_DTC_0x10000a_SetEventStatus: operation=Event_DTC_0x10000a.SetEventStatus
            SC_Event_DTC_0x10000b_SetEventStatus: operation=Event_DTC_0x10000b.SetEventStatus
            SC_Event_DTC_0xe40000_SetEventStatus: operation=Event_DTC_0xe40000.SetEventStatus
            SC_Event_DTC_0xe{40011..40013}_SetEventStatus: operation=Event_DTC_0xe{40011..40013}.SetEventStatus
            SC_OpCycle_RT_Test_OpCycle_GetOperationCycleState: operation=OpCycle_RT_Test_OpCycle.GetOperationCycleState
            SC_OpCycle_RT_Test_OpCycle_SetOperationCycleState: operation=OpCycle_RT_Test_OpCycle.SetOperationCycleState
            SC_Event_DTC_0xd{12000..12002}_SetEventStatus: operation=Event_DTC_0xd{12000..12002}.SetEventStatus
            SC_Event_DTC_0xd12004_SetEventStatus: operation=Event_DTC_0xd12004.SetEventStatus
            SC_Event_DTC_0xd12011_SetEventStatus: operation=Event_DTC_0xd12011.SetEventStatus
            SC_Event_DTC_0xd12025_SetEventStatus: operation=Event_DTC_0xd12025.SetEventStatus
            SC_Event_DTC_0xd12026_SetEventStatus: operation=Event_DTC_0xd12026.SetEventStatus
            SC_Event_DTC_0xd{12101..12103}_SetEventStatus: operation=Event_DTC_0xd{12101..12103}.SetEventStatus
            SC_ClearDTC_DemClient_DCM_ClearDTC: operation=ClearDTC_DemClient_DCM.ClearDTC
            SC_ClearDTC_DemClient_DCM_SelectDTC: operation=ClearDTC_DemClient_DCM.SelectDTC
            SC_Event_DTC_0xd12000_GetDTCOfEvent: operation=Event_DTC_0xd12000.GetDTCOfEvent
            SC_Event_DTC_0xd12000_GetEventExtendedDataRecordEx: operation=Event_DTC_0xd12000.GetEventExtendedDataRecordEx
            SC_Event_DTC_0xd12000_GetEventStatus: operation=Event_DTC_0xd12000.GetEventStatus
            SC_ControlDTCSuppression_DemClient_DCM_GetDTCSuppression: operation=ControlDTCSuppression_DemClient_DCM.GetDTCSuppression
            SC_ControlDTCSuppression_DemClient_DCM_SetDTCSuppression: operation=ControlDTCSuppression_DemClient_DCM.SetDTCSuppression
        DataServices_Data_TABROW_CanTPData_Read_WriteData
        DataServices_Data_TABROW_CanTPData_Read_ConditionCheckRead
        DataServices_Data_TABROW_CanTPData_Read_ReadData
        DataServices_Data_TABROW_PIMDID_Read_WriteData
        DataServices_Data_TABROW_PIMDID_Read_ConditionCheckRead
        DataServices_Data_TABROW_PIMDID_Read_ReadData
        RoutineServices_Routine_DiagnServi_TABROW_NewRoutiBasicSetti_Start_Routine_RequestResults
        RoutineServices_Routine_DiagnServi_TABROW_NewRoutiBasicSetti_Start_Routine_Stop
        RoutineServices_Routine_DiagnServi_TABROW_NewRoutiBasicSetti_Start_Routine_Start
        SecurityAccess_UnLock_L2_CompareKey
        SecurityAccess_UnLock_L2_GetSeed
        DataServices_Data_DiagnServi_TABROW_VWDataSetNumbeOrECUDataContaNumbe_Read_WriteData
        DataServices_Data_DiagnServi_TABROW_VWDataSetNumbeOrECUDataContaNumbe_Read_ConditionCheckRead
        DataServices_Data_DiagnServi_TABROW_VWDataSetNumbeOrECUDataContaNumbe_Read_ReadData
  swc implementation RT_Vishnu_Implementation: behavior=RT_Vishnu_InternalBehavior
